# MCXN947_cm33_core0 register map
Vendor: nxp.com; File version: 1.0
CPU: CM33 r2p0, little endian, MPU, FPU, VTOR, 3 interrupt priority bits
Registers are 32-bit, read-write, reset 0x0 unless marked. A register's access mark holds for its fields unless they carry their own. Offsets are from the block's base; [hi:lo] are bit positions; {n}, {i} and the like mark numbered series; 'fields as' and 'values as' point back to an identical list.

## PWM0 — PWM
Base 0x400CE000
Same registers: PWM1 0x400D0000
{0x0+0x60*i} SM{i}CNT 16-bit ro (i=0..3) — Counter Register
  [15:0] CNT — Counter Register Bits
{0x2+0x60*i} SM{i}INIT 16-bit (i=0..3) — Initial Count Register
  [15:0] INIT — Initial Count Register Bits
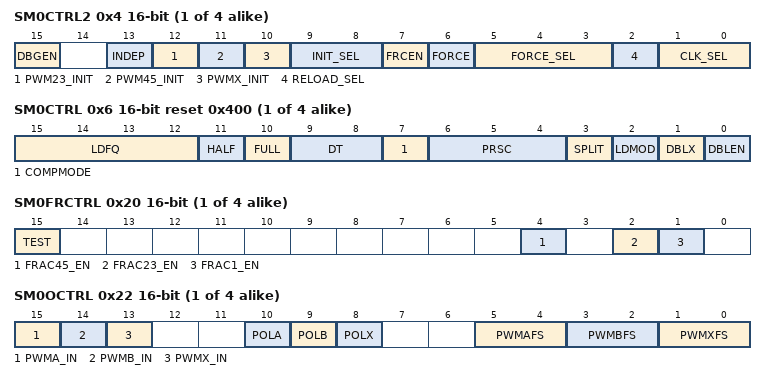
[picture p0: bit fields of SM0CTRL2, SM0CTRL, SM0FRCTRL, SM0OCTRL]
{0x4+0x60*i} SM{i}CTRL2 16-bit (i=0..3) — Control 2 Register
  [15] DBGEN — Debug Enable
  [13] INDEP — Independent or Complementary Pair Operation
    0=COMPLEMENTARY (PWM_A and PWM_B form a complementary PWM pair.); 1=INDEPENDENT (PWM_A and PWM_B outputs are independent PWMs.)
  [12] PWM23_INIT — PWM23 Initial Value
  [11] PWM45_INIT — PWM45 Initial Value
  [10] PWMX_INIT — PWM_X Initial Value
  [9:8] INIT_SEL — Initialization Control Select
    0=PWM_X (Local sync (PWM_X) causes initialization.); 1=MASTER_RELOAD (Master reload from submodule 0 causes initialization. This setting should not be used in submodule 0 as it forces the INIT signal to logic 0. The submodule counter will only re-initialize when a master reload occurs.); 2=MASTER_SYNC (Master sync from submodule 0 causes initialization. This setting should not be used in submodule 0 as it forces the INIT signal to logic 0.); 3=EXT_SYNC (EXT_SYNC causes initialization.)
  [7] FRCEN — Force Enable
    0=DISABLED (Initialization from a FORCE_OUT is disabled.); 1=ENABLED (Initialization from a FORCE_OUT is enabled.)
  [6] FORCE — Force Initialization
  [5:3] FORCE_SEL — Force Select
    0=LOCAL (The local force signal, CTRL2[FORCE], from this submodule is used to force updates.); 1=MASTER (The master force signal from submodule 0 is used to force updates. This setting should not be used in submodule 0 as it holds the FORCE OUTPUT signal to logic 0.); 2=LOCAL_RELOAD (The local reload signal from this submodule is used to force updates without regard to the state of LDOK.); 3=MASTER_RELOAD (The master reload signal from submodule0 is used to force updates if LDOK is set. This setting should not be used in submodule0 as it holds the FORCE OUTPUT signal to logic 0.); 4=LOCAL_SYNC (The local sync signal from this submodule is used to force updates.); 5=MASTER_SYNC (The master sync signal from submodule0 is used to force updates. This setting should not be used in submodule0 as it holds the FORCE OUTPUT signal to logic 0.); 6=EXT_FORCE (The external force signal, EXT_FORCE, from outside the PWM module causes updates.); 7=EXT_SYNC (The external sync signal, EXT_SYNC, from outside the PWM module causes updates.)
  [2] RELOAD_SEL — Reload Source Select
    0=LOCAL (The local RELOAD signal is used to reload registers.); 1=MASTER (The master RELOAD signal (from submodule 0) is used to reload registers. This setting should not be used in submodule 0 as it forces the RELOAD signal to logic 0.)
  [1:0] CLK_SEL — Clock Source Select
    0=IPBUS (The IPBus clock is used as the clock for the local prescaler and counter.); 1=EXT_CLK (EXT_CLK is used as the clock for the local prescaler and counter.); 2=AUX_CLK (Submodule 0's clock (AUX_CLK) is used as the source clock for the local prescaler and counter. This setting should not be used in submodule 0 as it forces the clock to logic 0.)
{0x6+0x60*i} SM{i}CTRL 16-bit reset 0x400 (i=0..3) — Control Register
  [15:12] LDFQ — Load Frequency
    0=EVERYPWM (Every PWM opportunity); {v}=EVERY{v+1}PWM (Every {v+1} PWM opportunities) (v=1..15)
  [11] HALF — Half Cycle Reload
    0=DISABLED (Half-cycle reloads disabled.); 1=ENABLED (Half-cycle reloads enabled.)
  [10] FULL — Full Cycle Reload
    0=DISABLED (Full-cycle reloads disabled.); 1=ENABLED (Full-cycle reloads enabled.)
  [9:8] DT ro — Deadtime
  [7] COMPMODE — Compare Mode
    0=EQUAL_TO (The VAL* registers and the PWM counter are compared using an "equal to" method. This means that PWM edges are only produced when the counter is equal to one of the VAL* register values. This implies that a PWM_A output that is high at the end of a period maintains this state until a match with VAL3 clears the output in the following period.); 1=EQUAL_TO_OR_GREATER_THAN (The VAL* registers and the PWM counter are compared using an "equal to or greater than" method. This means that PWM edges are produced when the counter is equal to or greater than one of the VAL* register values. This implies that a PWM_A output that is high at the end of a period could go low at the start of the next period if the starting counter value is greater than (but not necessarily equal to) the new VAL3 value.)
  [6:4] PRSC — Prescaler
    0=ONE (Prescaler 1); 1=TWO (Prescaler 2); 2=FOUR (Prescaler 4); 3=EIGHT (Prescaler 8); 4=SIXTEEN (Prescaler 16); 5=THIRTYTWO (Prescaler 32); 6=SIXTYFOUR (Prescaler 64); 7=HUNDREDTWENTYEIGHT (Prescaler 128)
  [3] SPLIT — Split the DBLPWM signal to PWM_A and PWM_B
    0=DISABLED (DBLPWM is not split. PWM_A and PWM_B each have double pulses.); 1=ENABLED (DBLPWM is split to PWM_A and PWM_B.)
  [2] LDMOD — Load Mode Select
    0=NEXT_PWM_RELOAD (Buffered registers of this submodule are loaded and take effect at the next PWM reload if MCTRL[LDOK] is set.); 1=MTCTRL_LDOK_SET (Buffered registers of this submodule are loaded and take effect immediately upon MCTRL[LDOK] being set. In this case, it is not necessary to set CTRL[FULL] or CTRL[HALF].)
  [1] DBLX — PWM_X Double Switching Enable
    0=DISABLED (PWM_X double pulse disabled.); 1=ENABLED (PWM_X double pulse enabled.)
  [0] DBLEN — Double Switching Enable
    0=DISABLED (Double switching disabled.); 1=ENABLED (Double switching enabled.)
{0xA+4i} SM0VAL{i} 16-bit (i=0..5) — Value Register {i}
  [15:0] VAL{i} — Value {i}
{0x8+4i} SM0FRACVAL{i} 16-bit (i=1..5) — Fractional Value Register {i}
  [15:11] FRACVAL{i} — Fractional Value {i}
{0x20+0x60*i} SM{i}FRCTRL 16-bit (i=0..3) — Fractional Control Register
  [15] TEST ro — Test Status Bit
  [4] FRAC45_EN — Fractional Cycle Placement Enable for PWM_B
    0=DISABLED (Disable fractional cycle placement for PWM_B.); 1=ENABLED (Enable fractional cycle placement for PWM_B.)
  [2] FRAC23_EN — Fractional Cycle Placement Enable for PWM_A
    0=DISABLED (Disable fractional cycle placement for PWM_A.); 1=ENABLED (Enable fractional cycle placement for PWM_A.)
  [1] FRAC1_EN — Fractional Cycle PWM Period Enable
    0=DISABLED (Disable fractional cycle length for the PWM period.); 1=ENABLED (Enable fractional cycle length for the PWM period.)
{0x22+0x60*i} SM{i}OCTRL 16-bit (i=0..3) — Output Control Register
  [15] PWMA_IN ro — PWM_A Input
  [14] PWMB_IN ro — PWM_B Input
  [13] PWMX_IN ro — PWM_X Input
  [10] POLA — PWM_A Output Polarity
    0=NOT_INVERTED (PWM_A output not inverted. A high level on the PWM_A pin represents the "on" or "active" state.); 1=INVERTED (PWM_A output inverted. A low level on the PWM_A pin represents the "on" or "active" state.)
  [9] POLB — PWM_B Output Polarity
    0=NOT_INVERTED (PWM_B output not inverted. A high level on the PWM_B pin represents the "on" or "active" state.); 1=INVERTED (PWM_B output inverted. A low level on the PWM_B pin represents the "on" or "active" state.)
  [8] POLX — PWM_X Output Polarity
    0=NOT_INVERTED (PWM_X output not inverted. A high level on the PWM_X pin represents the "on" or "active" state.); 1=INVERTED (PWM_X output inverted. A low level on the PWM_X pin represents the "on" or "active" state.)
  [5:4] PWMAFS — PWM_A Fault State
    0=LOGIC_0 (Output is forced to logic 0 state prior to consideration of output polarity control.); 1=LOGIC_1 (Output is forced to logic 1 state prior to consideration of output polarity control.); 2=TRISTATED_2 (Output is put in a high-impedance state.); 3=TRISTATED_3 (Output is put in a high-impedance state.)
  [3:2] PWMBFS — PWM_B Fault State
    values as PWMAFS
  [1:0] PWMXFS — PWM_X Fault State
    values as PWMAFS
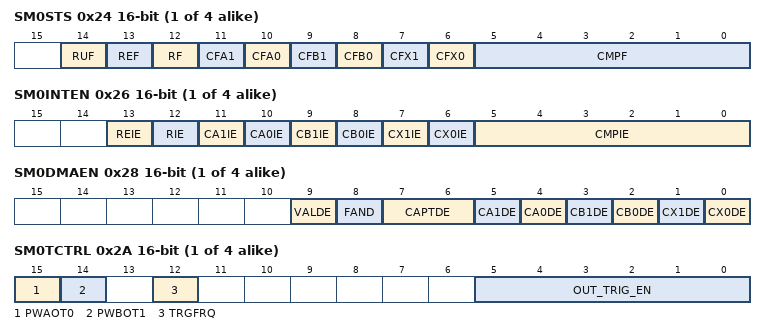
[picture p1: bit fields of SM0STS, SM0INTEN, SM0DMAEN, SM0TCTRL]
{0x24+0x60*i} SM{i}STS 16-bit (i=0..3) — Status Register
  [14] RUF ro — Registers Updated Flag
    0=NO_FLAG (No register update has occurred since last reload.); 1=FLAG (At least one of the double buffered registers has been updated since the last reload.)
  [13] REF write-1-clears — Reload Error Flag
    0=NO_FLAG (No reload error occurred.); 1=FLAG (Reload signal occurred with non-coherent data and MCTRL[LDOK] = 0.)
  [12] RF write-1-clears — Reload Flag
    0=NO_FLAG (No new reload cycle since last STS[RF] clearing); 1=FLAG (New reload cycle since last STS[RF] clearing)
  [11] CFA1 write-1-clears — Capture Flag A1
  [10] CFA0 write-1-clears — Capture Flag A0
  [9] CFB1 write-1-clears — Capture Flag B1
  [8] CFB0 write-1-clears — Capture Flag B0
  [7] CFX1 write-1-clears — Capture Flag X1
  [6] CFX0 write-1-clears — Capture Flag X0
  [5:0] CMPF write-1-clears — Compare Flags
    0=NO_EVENT (No compare event has occurred for a particular VALx value.); 1=EVENT (A compare event has occurred for a particular VALx value.)
{0x26+0x60*i} SM{i}INTEN 16-bit (i=0..3) — Interrupt Enable Register
  [13] REIE — Reload Error Interrupt Enable
    0=DISABLED (STS[REF] CPU interrupt requests disabled); 1=ENABLED (STS[REF] CPU interrupt requests enabled)
  [12] RIE — Reload Interrupt Enable
    0=DISABLED (STS[RF] CPU interrupt requests disabled); 1=ENABLED (STS[RF] CPU interrupt requests enabled)
  [11] CA1IE — Capture A 1 Interrupt Enable
    0=DISABLED (Interrupt request disabled for STS[CFA1]); 1=ENABLED (Interrupt request enabled for STS[CFA1])
  [10] CA0IE — Capture A 0 Interrupt Enable
    0=DISABLED (Interrupt request disabled for STS[CFA0].); 1=ENABLED (Interrupt request enabled for STS[CFA0].)
  [9] CB1IE — Capture B 1 Interrupt Enable
    0=DISABLED (Interrupt request disabled for STS[CFB1].); 1=ENABLED (Interrupt request enabled for STS[CFB1].)
  [8] CB0IE — Capture B 0 Interrupt Enable
    0=DISABLED (Interrupt request disabled for STS[CFB0].); 1=ENABLED (Interrupt request enabled for STS[CFB0].)
  [7] CX1IE — Capture X 1 Interrupt Enable
    0=DISABLED (Interrupt request disabled for STS[CFX1].); 1=ENABLED (Interrupt request enabled for STS[CFX1].)
  [6] CX0IE — Capture X 0 Interrupt Enable
    0=DISABLED (Interrupt request disabled for STS[CFX0].); 1=ENABLED (Interrupt request enabled for STS[CFX0].)
  [5:0] CMPIE — Compare Interrupt Enables
    0=DISABLED (The corresponding STS[CMPF] bit will not cause an interrupt request.); 1=ENABLED (The corresponding STS[CMPF] bit will cause an interrupt request.)
{0x28+0x60*i} SM{i}DMAEN 16-bit (i=0..3) — DMA Enable Register
  [9] VALDE — Value Registers DMA Enable
    0=DISABLED (DMA write requests disabled); 1=ENABLED
  [8] FAND — FIFO Watermark AND Control
    0=OR (Selected FIFO watermarks are OR'ed together.); 1=AND (Selected FIFO watermarks are AND'ed together.)
  [7:6] CAPTDE — Capture DMA Enable Source Select
    0=DISABLED (Read DMA requests disabled.); 1=EXCEEDFIFO (Exceeding a FIFO watermark sets the DMA read request. This requires at least one of DMAEN[CA1DE], DMAEN[CA0DE], DMAEN[CB1DE], DMAEN[CB0DE], DMAEN[CX1DE], or DMAEN[CX0DE] to be set to determine which watermark(s) the DMA request is sensitive.); 2=LOCAL_SYNC (A local synchronization (VAL1 matches counter) sets the read DMA request.); 3=LOCAL_RELOAD (A local reload (STS[RF] being set) sets the read DMA request.)
  [5] CA1DE — Capture A1 FIFO DMA Enable
  [4] CA0DE — Capture A0 FIFO DMA Enable
  [3] CB1DE — Capture B1 FIFO DMA Enable
  [2] CB0DE — Capture B0 FIFO DMA Enable
  [1] CX1DE — Capture X1 FIFO DMA Enable
  [0] CX0DE — Capture X0 FIFO DMA Enable
{0x2A+0x60*i} SM{i}TCTRL 16-bit (i=0..3) — Output Trigger Control Register
  [15] PWAOT0 — Mux Output Trigger 0 Source Select
    0=PWM_OUT_TRIG0_SIGNAL (Route the PWM_OUT_TRIG0 signal to PWM_MUX_TRIG0 port.); 1=PWMA_OUTPUT (Route the PWM_A output to the PWM_MUX_TRIG0 port.)
  [14] PWBOT1 — Mux Output Trigger 1 Source Select
    0=PWM_OUT_TRIG1_SIGNAL (Route the PWM_OUT_TRIG1 signal to PWM_MUX_TRIG1 port.); 1=PWMB_OUTPUT (Route the PWM_B output to the PWM_MUX_TRIG1 port.)
  [12] TRGFRQ — Trigger Frequency
    0=EVERYPWM (Trigger outputs are generated during every PWM period even if the PWM is not reloaded every period due to CTRL[LDFQ] being non-zero.); 1=FINALPWM (Trigger outputs are generated only during the final PWM period prior to a reload opportunity when the PWM is not reloaded every period due to CTRL[LDFQ] being non-zero.)
  [5:0] OUT_TRIG_EN — Output Trigger Enables
    0bxxxxx1=PWM_OUT_TRIG0 will set when the counter value matches the VAL0 value
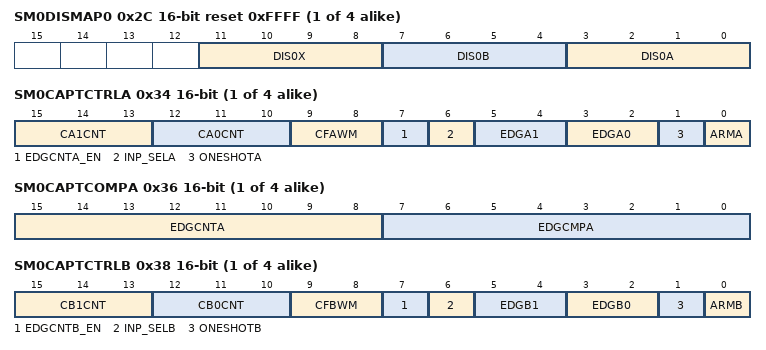
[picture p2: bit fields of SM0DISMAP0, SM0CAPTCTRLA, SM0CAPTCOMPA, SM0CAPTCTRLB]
{0x2C+0x60*i} SM{i}DISMAP0 16-bit reset 0xFFFF (i=0..3) — Fault Disable Mapping Register 0
  [11:8] DIS0X — PWM_X Fault Disable Mask 0
  [7:4] DIS0B — PWM_B Fault Disable Mask 0
  [3:0] DIS0A — PWM_A Fault Disable Mask 0
{0x30+0x60*i} SM{i}DTCNT0 16-bit reset 0x7FF (i=0..3) — Deadtime Count Register 0
  [10:0] DTCNT0
{0x32+0x60*i} SM{i}DTCNT1 16-bit reset 0x7FF (i=0..3) — Deadtime Count Register 1
  [10:0] DTCNT1
{0x34+0x60*i} SM{i}CAPTCTRLA 16-bit (i=0..3) — Capture Control A Register
  [15:13] CA1CNT ro — Capture A1 FIFO Word Count
  [12:10] CA0CNT ro — Capture A0 FIFO Word Count
  [9:8] CFAWM — Capture A FIFOs Water Mark
  [7] EDGCNTA_EN — Edge Counter A Enable
    0=DISABLED (Edge counter disabled and held in reset); 1=ENABLED (Edge counter enabled)
  [6] INP_SELA — Input Select A
    0=PWM_A (Raw PWM_A input signal selected as source.); 1=EDGE_COUNTER
  [5:4] EDGA1 — Edge A 1
    0=DISABLED; 1=FALLING_EDGE (Capture falling edges); 2=RISING_EDGE (Capture rising edges); 3=ANY_EDGE (Capture any edge)
  [3:2] EDGA0 — Edge A 0
    values as EDGA1
  [1] ONESHOTA — One Shot Mode A
    0=FREE_RUNNING; 1=ONE_SHOT
  [0] ARMA
    0=DISABLED (Input capture operation is disabled.); 1=ENABLED (Input capture operation as specified by CAPTCTRLA[EDGAx] is enabled.)
{0x36+0x60*i} SM{i}CAPTCOMPA 16-bit (i=0..3) — Capture Compare A Register
  [15:8] EDGCNTA ro — Edge Counter A
  [7:0] EDGCMPA — Edge Compare A
{0x38+0x60*i} SM{i}CAPTCTRLB 16-bit (i=0..3) — Capture Control B Register
  [15:13] CB1CNT ro — Capture B1 FIFO Word Count
  [12:10] CB0CNT ro — Capture B0 FIFO Word Count
  [9:8] CFBWM — Capture B FIFOs Water Mark
  [7] EDGCNTB_EN — Edge Counter B Enable
    values as SM0CAPTCTRLA.EDGCNTA_EN
  [6] INP_SELB — Input Select B
    0=PWM_B (Raw PWM_B input signal selected as source.); 1=EDGE_COUNTER
  [5:4] EDGB1 — Edge B 1
    values as SM0CAPTCTRLA.EDGA1
  [3:2] EDGB0 — Edge B 0
    values as SM0CAPTCTRLA.EDGA1
  [1] ONESHOTB — One Shot Mode B
    0=FREE_RUNNING; 1=ONE_SHOT
  [0] ARMB
    0=DISABLED (Input capture operation is disabled.); 1=ENABLED (Input capture operation as specified by CAPTCTRLB[EDGBx] is enabled.)
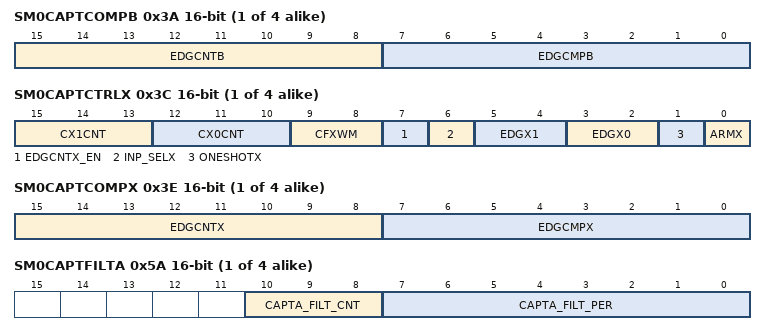
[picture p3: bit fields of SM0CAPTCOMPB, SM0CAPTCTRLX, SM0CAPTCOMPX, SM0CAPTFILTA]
{0x3A+0x60*i} SM{i}CAPTCOMPB 16-bit (i=0..3) — Capture Compare B Register
  [15:8] EDGCNTB ro — Edge Counter B
  [7:0] EDGCMPB — Edge Compare B
{0x3C+0x60*i} SM{i}CAPTCTRLX 16-bit (i=0..3) — Capture Control X Register
  [15:13] CX1CNT ro — Capture X1 FIFO Word Count
  [12:10] CX0CNT ro — Capture X0 FIFO Word Count
  [9:8] CFXWM — Capture X FIFOs Water Mark
  [7] EDGCNTX_EN — Edge Counter X Enable
    values as SM0CAPTCTRLA.EDGCNTA_EN
  [6] INP_SELX — Input Select X
    0=PWM_X (Raw PWM_X input signal selected as source.); 1=EDGE_COUNTER
  [5:4] EDGX1 — Edge X 1
    values as SM0CAPTCTRLA.EDGA1
  [3:2] EDGX0 — Edge X 0
    values as SM0CAPTCTRLA.EDGA1
  [1] ONESHOTX — One Shot Mode Aux
    0=FREE_RUNNING; 1=ONE_SHOT
  [0] ARMX
    0=DISABLED (Input capture operation is disabled.); 1=ENABLED (Input capture operation as specified by CAPTCTRLX[EDGXx] is enabled.)
{0x3E+0x60*i} SM{i}CAPTCOMPX 16-bit (i=0..3) — Capture Compare X Register
  [15:8] EDGCNTX ro — Edge Counter X
  [7:0] EDGCMPX — Edge Compare X
{0x40+4i} SM0CVAL{i} 16-bit ro (i=0..5) — Capture Value {i} Register
  [15:0] CAPTVAL{i} — Capture Value {i}
{0x42+4i} SM0CVAL{i}CYC 16-bit ro (i=0..5) — Capture Value {i} Cycle Register
  [3:0] CVAL{i}CYC — Capture Value {i} Cycle
{0x5A+0x60*i} SM{i}CAPTFILTA 16-bit (i=0..3) — Capture PWM_A Input Filter Register
  [10:8] CAPTA_FILT_CNT — Fault Filter Count
  [7:0] CAPTA_FILT_PER — Fault Filter Period
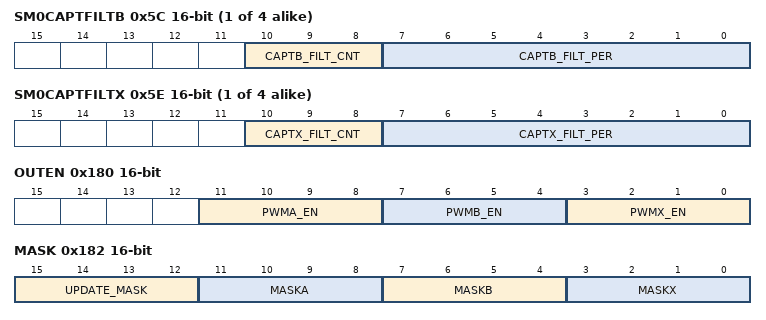
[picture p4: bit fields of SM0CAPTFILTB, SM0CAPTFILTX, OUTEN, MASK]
{0x5C+0x60*i} SM{i}CAPTFILTB 16-bit (i=0..3) — Capture PWM_B Input Filter Register
  [10:8] CAPTB_FILT_CNT — Fault Filter Count
  [7:0] CAPTB_FILT_PER — Fault Filter Period
{0x5E+0x60*i} SM{i}CAPTFILTX 16-bit (i=0..3) — Capture PWM_X Input Filter Register
  [10:8] CAPTX_FILT_CNT — Fault Filter Count
  [7:0] CAPTX_FILT_PER — Fault Filter Period
{0x6A+4i} SM1VAL{i} 16-bit (i=0..5) — Value Register {i}
  [15:0] VAL{i} — Value {i}
{0x68+4i} SM1FRACVAL{i} 16-bit (i=1..5) — Fractional Value Register {i}
  [15:11] FRACVAL{i} — Fractional Value {i}
{0xA0+4i} SM1CVAL{i} 16-bit ro (i=0..5) — Capture Value {i} Register
  [15:0] CAPTVAL{i} — Capture Value {i}
{0xA2+4i} SM1CVAL{i}CYC 16-bit ro (i=0..5) — Capture Value {i} Cycle Register
  [3:0] CVAL{i}CYC — Capture Value {i} Cycle
{0x58+0x60*i} SM{i}PHASEDLY 16-bit (i=1..3) — Phase Delay Register
  [15:0] PHASEDLY — Initial Count Register Bits
{0xCA+4i} SM2VAL{i} 16-bit (i=0..5) — Value Register {i}
  [15:0] VAL{i} — Value {i}
{0xC8+4i} SM2FRACVAL{i} 16-bit (i=1..5) — Fractional Value Register {i}
  [15:11] FRACVAL{i} — Fractional Value {i}
{0x100+4i} SM2CVAL{i} 16-bit ro (i=0..5) — Capture Value {i} Register
  [15:0] CAPTVAL{i} — Capture Value {i}
{0x102+4i} SM2CVAL{i}CYC 16-bit ro (i=0..5) — Capture Value {i} Cycle Register
  [3:0] CVAL{i}CYC — Capture Value {i} Cycle
{0x12A+4i} SM3VAL{i} 16-bit (i=0..5) — Value Register {i}
  [15:0] VAL{i} — Value {i}
{0x128+4i} SM3FRACVAL{i} 16-bit (i=1..5) — Fractional Value Register {i}
  [15:11] FRACVAL{i} — Fractional Value {i}
{0x160+4i} SM3CVAL{i} 16-bit ro (i=0..5) — Capture Value {i} Register
  [15:0] CAPTVAL{i} — Capture Value {i}
{0x162+4i} SM3CVAL{i}CYC 16-bit ro (i=0..5) — Capture Value {i} Cycle Register
  [3:0] CVAL{i}CYC — Capture Value {i} Cycle
0x180 OUTEN 16-bit — Output Enable Register
  [11:8] PWMA_EN — PWM_A Output Enables
    0=DISABLED (PWM_A output disabled.); 1=ENABLED (PWM_A output enabled.)
  [7:4] PWMB_EN — PWM_B Output Enables
    0=DISABLED (PWM_B output disabled.); 1=ENABLED (PWM_B output enabled.)
  [3:0] PWMX_EN — PWM_X Output Enables
    0=DISABLED (PWM_X output disabled.); 1=ENABLED (PWM_X output enabled.)
0x182 MASK 16-bit
  [15:12] UPDATE_MASK wo — Update Mask Bits Immediately
    0=NORMAL (Normal operation. MASK* bits within the corresponding submodule are not updated until a FORCE_OUT event occurs within the submodule.); 1=MASK_IMMEDIATE (Immediate operation. MASK* bits within the corresponding submodule are updated on the following clock edge after setting this bit.)
  [11:8] MASKA — PWM_A Masks
    0=NORMAL (PWM_A output normal.); 1=MASKED (PWM_A output masked.)
  [7:4] MASKB — PWM_B Masks
    0=NORMAL (PWM_B output normal.); 1=MASKED (PWM_B output masked.)
  [3:0] MASKX — PWM_X Masks
    0=NORMAL (PWM_X output normal.); 1=MASKED (PWM_X output masked.)
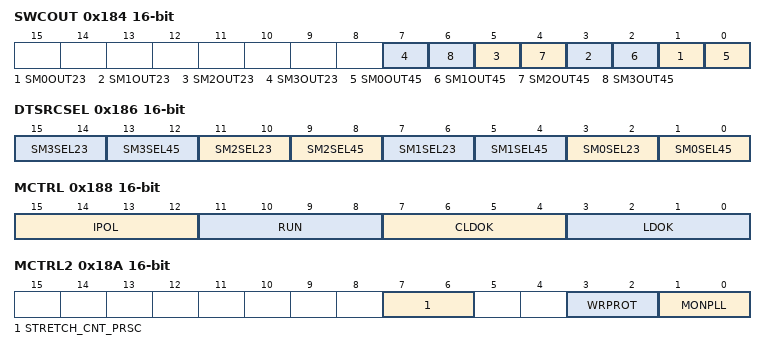
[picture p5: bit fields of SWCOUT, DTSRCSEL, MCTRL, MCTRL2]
0x184 SWCOUT 16-bit — Software Controlled Output Register
  [2n+1] SM{n}OUT23 (n=0..3) — Submodule {n} Software Controlled Output 23
    0=LOGIC_0 (A logic 0 is supplied to the deadtime generator of submodule {n} instead of PWM23.); 1=LOGIC_1 (A logic 1 is supplied to the deadtime generator of submodule {n} instead of PWM23.)
  [2n] SM{n}OUT45 (n=0..3) — Submodule {n} Software Controlled Output 45
    0=LOGIC_0 (A logic 0 is supplied to the deadtime generator of submodule {n} instead of PWM45.); 1=LOGIC_1 (A logic 1 is supplied to the deadtime generator of submodule {n} instead of PWM45.)
0x186 DTSRCSEL 16-bit — PWM Source Select Register
  [4n+3:4n+2] SM{n}SEL23 (n=0..3) — Submodule {n} PWM23 Control Select
    0=SM{n}PWM23 (Generated SM{n}PWM23 signal used by the deadtime logic.); 1=INVERTED_SM{n}PWM23 (Inverted generated SM{n}PWM23 signal used by the deadtime logic.); 2=SM{n}OUT23 (SWCOUT[SM{n}OUT23] used by the deadtime logic.); 3=PWM{n}_EXTA (PWM{n}_EXTA signal used by the deadtime logic.)
  [4n+1:4n] SM{n}SEL45 (n=0..3) — Submodule {n} PWM45 Control Select
    0=SM{n}PWM45 (Generated SM{n}PWM45 signal used by the deadtime logic.); 1=INVERTED_SM{n}PWM45 (Inverted generated SM{n}PWM45 signal used by the deadtime logic.); 2=SM{n}OUT45 (SWCOUT[SM{n}OUT45] used by the deadtime logic.); 3=PWM{n}_EXTB (PWM{n}_EXTB signal used by the deadtime logic.)
0x188 MCTRL 16-bit — Master Control Register
  [15:12] IPOL — Current Polarity
    0=PWM23 (PWM23 is used to generate complementary PWM pair in the corresponding submodule.); 1=PWM45 (PWM45 is used to generate complementary PWM pair in the corresponding submodule.)
  [11:8] RUN
    0=DISABLED (PWM counter is stopped, but PWM outputs hold the current state.); 1=ENABLED (PWM counter is started in the corresponding submodule.)
  [7:4] CLDOK — Clear Load Okay
  [3:0] LDOK — Load Okay
    0=DISABLED (Do not load new values.); 1=ENABLED (Load prescaler, modulus, and PWM values of the corresponding submodule.)
0x18A MCTRL2 16-bit — Master Control 2 Register
  [7:6] STRETCH_CNT_PRSC — Stretch IPBus clock count prescaler for mux0_trig/mux1_trig/out0_trig/out1_trig/pwma_trig/pwmb_trig
    0=DISABLED (Stretch count is zero, no stretch.); 1=ENABLED (Stretch mux0_trig/mux1_trig/out0_trig/out1_trig/pwma_trig/pwmb_trig for 2 IPBus clock period.); 2=DISABLED_LOCKED (Stretch mux0_trig/mux1_trig/out0_trig/out1_trig/pwma_trig/pwmb_trig for 4 IPBus clock period.); 3=ENABLED_LOCKED (Stretch mux0_trig/mux1_trig/out0_trig/out1_trig/pwma_trig/pwmb_trig for 8 IPBus clock period.)
  [3:2] WRPROT — Write protect
    0=DISABLED (Write protection off (default).); 1=ENABLED (Write protection on.); 2=DISABLED_LOCKED (Write protection off and locked until chip reset.); 3=ENABLED_LOCKED (Write protection on and locked until chip reset.)
  [1:0] MONPLL — Monitor PLL State
    0=NOTLOCKED_DO_NOT_MON_PLL (Not locked. Do not monitor PLL operation. Resetting of the fractional delay block in case of PLL losing lock will be controlled by software.); 1=NOTLOCKED_MON_PLL (Not locked. Monitor PLL operation to automatically disable the fractional delay block when the PLL encounters problems.); 2=LOCKED_DO_NOT_MON_PLL (Locked. Do not monitor PLL operation. Resetting of the fractional delay block in case of PLL losing lock will be controlled by software. These bits are write protected until the next reset.); 3=LOCKED_MON_PLL (Locked. Monitor PLL operation to automatically disable the fractional delay block when the PLL encounters problems. These bits are write protected until the next reset.)
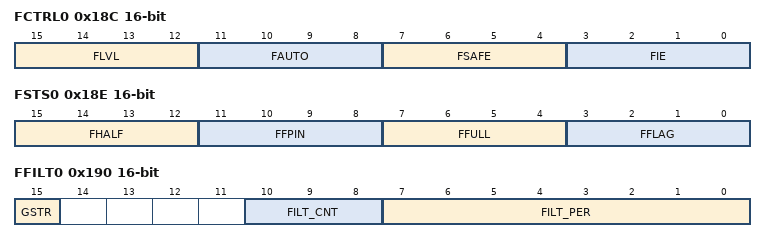
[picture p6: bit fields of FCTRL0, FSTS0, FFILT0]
0x18C FCTRL0 16-bit — Fault Control Register
  [15:12] FLVL — Fault Level
    0=LOGIC_0 (A logic 0 on the fault input indicates a fault condition.); 1=LOGIC_1 (A logic 1 on the fault input indicates a fault condition.)
  [11:8] FAUTO — Automatic Fault Clearing
    0=MANUAL (Manual fault clearing. PWM outputs disabled by this fault are not enabled until FSTS[FFLAGx] is clear at the start of a half cycle or full cycle depending on the states of FSTS[FHALF] and FSTS[FFULL]. If neither FFULL nor FHALF is set, then the fault condition cannot be cleared. This is further controlled by FCTRL[FSAFE].); 1=AUTOMATIC (Automatic fault clearing. PWM outputs disabled by this fault are enabled when FSTS[FFPINx] is clear at the start of a half cycle or full cycle depending on the states of FSTS[FHALF] and FSTS[FFULL] without regard to the state of FSTS[FFLAGx]. If neither FFULL nor FHALF is set, then the fault condition cannot be cleared.)
  [7:4] FSAFE — Fault Safety Mode
    0=NORMAL (Normal mode. PWM outputs disabled by this fault are not enabled until FSTS[FFLAGx] is clear at the start of a half cycle or full cycle depending on the states of FSTS[FHALF] and FSTS[FFULL] without regard to the state of FSTS[FFPINx]. If neither FHALF nor FFULL is set, then the fault condition cannot be cleared. The PWM outputs disabled by this fault input will not be re-enabled until the actual FAULTx input signal de-asserts since the fault input will combinationally disable the PWM outputs (as programmed in DISMAPn).); 1=SAFE (Safe mode. PWM outputs disabled by this fault are not enabled until FSTS[FFLAGx] is clear and FSTS[FFPINx] is clear at the start of a half cycle or full cycle depending on the states of FSTS[FHALF] and FSTS[FFULL]. If neither FHLAF nor FFULL is set, then the fault condition cannot be cleared.)
  [3:0] FIE — Fault Interrupt Enables
    0=DISABLED (FAULTx CPU interrupt requests disabled.); 1=ENABLED (FAULTx CPU interrupt requests enabled.)
0x18E FSTS0 16-bit (reset mask 0xF0F0) — Fault Status Register
  [15:12] FHALF — Half Cycle Fault Recovery
    0=PWM_OUTPUTS_NOT_REENABLED (PWM outputs are not re-enabled at the start of a half cycle.); 1=PWM_OUTPUTS_REENABLED (PWM outputs are re-enabled at the start of a half cycle (as defined by VAL0).)
  [11:8] FFPIN ro — Filtered Fault Pins
  [7:4] FFULL — Full Cycle
    0=PWM_OUTPUTS_NOT_REENABLED (PWM outputs are not re-enabled at the start of a full cycle); 1=PWM_OUTPUTS_REENABLED (PWM outputs are re-enabled at the start of a full cycle)
  [3:0] FFLAG — Fault Flags
    0=NO_FLAG (No fault on the FAULTx pin.); 1=FLAG (Fault on the FAULTx pin.)
0x190 FFILT0 16-bit — Fault Filter Register
  [15] GSTR — Fault Glitch Stretch Enable
    0=DISABLED (Fault input glitch stretching is disabled.); 1=ENABLED (Input fault signals are stretched to at least 2 IPBus clock cycles.)
  [10:8] FILT_CNT — Fault Filter Count
  [7:0] FILT_PER — Fault Filter Period
0x192 FTST0 16-bit — Fault Test Register
  [0] FTEST — Fault Test
    0=NO_FAULT; 1=FAULT (Cause a simulated fault)
0x194 FCTRL20 16-bit — Fault Control 2 Register
  [3:0] NOCOMB — No Combinational Path From Fault Input To PWM Output
    0=ENABLED (There is a combinational link from the fault inputs to the PWM outputs. The fault inputs are combined with the filtered and latched fault signals to disable the PWM outputs.); 1=DISABLED (The direct combinational path from the fault inputs to the PWM outputs is disabled and the filtered and latched fault signals are used to disable the PWM outputs.)
